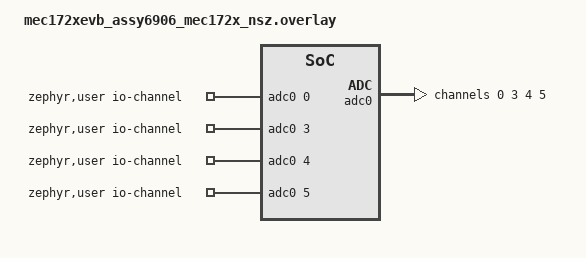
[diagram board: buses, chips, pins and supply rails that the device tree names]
/*
 * SPDX-License-Identifier: Apache-2.0
 *
 * Copyright (c) 2022 Intel Corporation
 */

/ {
	zephyr,user {
		io-channels =  <&adc0 0>, <&adc0 3>, <&adc0 4>, <&adc0 5>;
	};
};
&adc0 {
	#address-cells = <1>;
	#size-cells = <0>;

	channel@0 {
		reg = <0>;
		zephyr,gain = "ADC_GAIN_1";
		zephyr,reference = "ADC_REF_INTERNAL";
		zephyr,acquisition-time = <0>;
		zephyr,resolution = <12>;
	};
	channel@3 {
		reg = <3>;
		zephyr,gain = "ADC_GAIN_1";
		zephyr,reference = "ADC_REF_INTERNAL";
		zephyr,acquisition-time = <0>;
		zephyr,resolution = <12>;
	};
	channel@4 {
		reg = <4>;
		zephyr,gain = "ADC_GAIN_1";
		zephyr,reference = "ADC_REF_INTERNAL";
		zephyr,acquisition-time = <0>;
		zephyr,resolution = <12>;
	};
	channel@5 {
		reg = <5>;
		zephyr,gain = "ADC_GAIN_1";
		zephyr,reference = "ADC_REF_INTERNAL";
		zephyr,acquisition-time = <0>;
		zephyr,resolution = <12>;
	};
};
